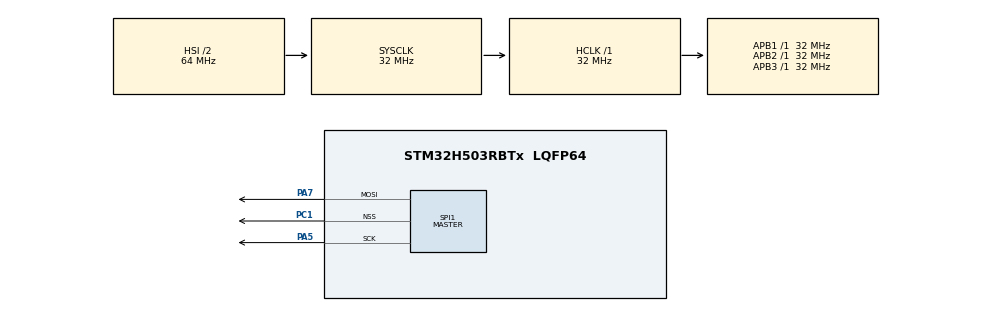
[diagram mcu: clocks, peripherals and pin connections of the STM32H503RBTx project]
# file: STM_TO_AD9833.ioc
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Mcu.Family=STM32H5
Mcu.Name=STM32H503RBTx
Mcu.Package=LQFP64
NVIC.PriorityGroup=NVIC_PRIORITYGROUP_4
PA5.Mode=TX_Only_Simplex_Unidirect_Master
PA5.Signal=SPI1_SCK
PA7.Mode=TX_Only_Simplex_Unidirect_Master
PA7.Signal=SPI1_MOSI
PC1.Mode=NSS_Signal_Hard_Output
PC1.Signal=SPI1_NSS
ProjectManager.HeapSize=0x200
ProjectManager.StackSize=0x400
ProjectManager.TargetToolchain=STM32CubeIDE
RCC.ADCFreq_Value=32000000
RCC.AHBFreq_Value=32000000
RCC.APB1Freq_Value=32000000
RCC.APB1TimFreq_Value=32000000
RCC.APB2Freq_Value=32000000
RCC.APB2TimFreq_Value=32000000
RCC.APB3Freq_Value=32000000
RCC.CSI_VALUE=4000000
RCC.CortexFreq_Value=32000000
RCC.EPOD_VALUE=4000000
RCC.HCLKFreq_Value=32000000
RCC.HSE_VALUE=25000000
RCC.HSI48_VALUE=48000000
RCC.HSI_VALUE=64000000
RCC.LSE_VALUE=32768
RCC.LSIRC_VALUE=32000
RCC.PLL1Q=3
RCC.PLLFRACN=0
RCC.PLLN=32
RCC.SYSCLKFreq_VALUE=32000000
RCC.USBFreq_Value=48000000
RCC.VCOOutputFreq_Value=128000000
SPI1.BaudRatePrescaler=SPI_BAUDRATEPRESCALER_4
SPI1.CLKPolarity=SPI_POLARITY_HIGH
SPI1.CalculateBaudRate=10.666666 MBits/s
SPI1.DataSize=SPI_DATASIZE_8BIT
SPI1.Direction=SPI_DIRECTION_2LINES_TXONLY
SPI1.Mode=SPI_MODE_MASTER
SPI1.VirtualNSS=VM_NSSHARD
SPI1.VirtualType=VM_MASTER
VP_BOOTPATH_VS_BOOTPATH.Mode=BP_Activate
VP_CORTEX_M33_NS_VS_Hclk.Mode=Hclk_Mode
VP_MEMORYMAP_VS_MEMORYMAP.Mode=CurAppReg
VP_PWR_VS_LPOM.Mode=PowerOptimisation
VP_PWR_VS_SECSignals.Mode=Security/Privilege
board=custom

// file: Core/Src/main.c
/* USER CODE BEGIN Header */
/**
  ******************************************************************************
  * @file           : main.c
  * @brief          : Main program body
  ******************************************************************************
  * @attention
  *
  * Copyright (c) 2026 STMicroelectronics.
  * All rights reserved.
  *
  * This software is licensed under terms that can be found in the LICENSE file
  * in the root directory of this software component.
  * If no LICENSE file comes with this software, it is provided AS-IS.
  *
  ******************************************************************************
  */
/* USER CODE END Header */
#include "main.h"

/* USER CODE BEGIN Includes */
#include "AD9833.h"
/* USER CODE END Includes */

SPI_HandleTypeDef hspi1;

void SystemClock_Config(void);
static void MX_GPIO_Init(void);
static void MX_SPI1_Init(void);

int main(void)
{

  /* MCU Configuration--------------------------------------------------------*/

  /* Reset of all peripherals, Initializes the Flash interface and the Systick. */
  HAL_Init();

  /* Configure the system clock */
  SystemClock_Config();

  /* Initialize all configured peripherals */
  MX_GPIO_Init();
  MX_SPI1_Init();
  /* USER CODE BEGIN 2 */
  AD9833_Init(wave_square, 50000, 0);
  /* USER CODE END 2 */

  /* Infinite loop */
  while (1)
  {

  }
}

void SystemClock_Config(void)
{
  RCC_OscInitTypeDef RCC_OscInitStruct = {0};
  RCC_ClkInitTypeDef RCC_ClkInitStruct = {0};

  /** Configure the main internal regulator output voltage
  */
  __HAL_PWR_VOLTAGESCALING_CONFIG(PWR_REGULATOR_VOLTAGE_SCALE3);

  while(!__HAL_PWR_GET_FLAG(PWR_FLAG_VOSRDY)) {}

  /** Initializes the RCC Oscillators according to the specified parameters
  * in the RCC_OscInitTypeDef structure.
  */
  RCC_OscInitStruct.OscillatorType = RCC_OSCILLATORTYPE_HSI|RCC_OSCILLATORTYPE_CSI;
  RCC_OscInitStruct.HSIState = RCC_HSI_ON;
  RCC_OscInitStruct.HSIDiv = RCC_HSI_DIV2;
  RCC_OscInitStruct.HSICalibrationValue = RCC_HSICALIBRATION_DEFAULT;
  RCC_OscInitStruct.CSIState = RCC_CSI_ON;
  RCC_OscInitStruct.CSICalibrationValue = RCC_CSICALIBRATION_DEFAULT;
  RCC_OscInitStruct.PLL.PLLState = RCC_PLL_ON;
  RCC_OscInitStruct.PLL.PLLSource = RCC_PLL1_SOURCE_CSI;
  RCC_OscInitStruct.PLL.PLLM = 1;
  RCC_OscInitStruct.PLL.PLLN = 32;
  RCC_OscInitStruct.PLL.PLLP = 2;
  RCC_OscInitStruct.PLL.PLLQ = 3;
  RCC_OscInitStruct.PLL.PLLR = 2;
  RCC_OscInitStruct.PLL.PLLRGE = RCC_PLL1_VCIRANGE_2;
  RCC_OscInitStruct.PLL.PLLVCOSEL = RCC_PLL1_VCORANGE_WIDE;
  RCC_OscInitStruct.PLL.PLLFRACN = 0;
  if (HAL_RCC_OscConfig(&RCC_OscInitStruct) != HAL_OK)
  {
    Error_Handler();
  }

  /** Initializes the CPU, AHB and APB buses clocks
  */
  RCC_ClkInitStruct.ClockType = RCC_CLOCKTYPE_HCLK|RCC_CLOCKTYPE_SYSCLK
                              |RCC_CLOCKTYPE_PCLK1|RCC_CLOCKTYPE_PCLK2
                              |RCC_CLOCKTYPE_PCLK3;
  RCC_ClkInitStruct.SYSCLKSource = RCC_SYSCLKSOURCE_HSI;
  RCC_ClkInitStruct.AHBCLKDivider = RCC_SYSCLK_DIV1;
  RCC_ClkInitStruct.APB1CLKDivider = RCC_HCLK_DIV1;
  RCC_ClkInitStruct.APB2CLKDivider = RCC_HCLK_DIV1;
  RCC_ClkInitStruct.APB3CLKDivider = RCC_HCLK_DIV1;

  if (HAL_RCC_ClockConfig(&RCC_ClkInitStruct, FLASH_LATENCY_1) != HAL_OK)
  {
    Error_Handler();
  }

  /** Configure the programming delay
  */
  __HAL_FLASH_SET_PROGRAM_DELAY(FLASH_PROGRAMMING_DELAY_0);
}

static void MX_SPI1_Init(void)
{

  /* SPI1 parameter configuration*/
  hspi1.Instance = SPI1;
  hspi1.Init.Mode = SPI_MODE_MASTER;
  hspi1.Init.Direction = SPI_DIRECTION_2LINES_TXONLY;
  hspi1.Init.DataSize = SPI_DATASIZE_8BIT;
  hspi1.Init.CLKPolarity = SPI_POLARITY_HIGH;
  hspi1.Init.CLKPhase = SPI_PHASE_1EDGE;
  hspi1.Init.NSS = SPI_NSS_HARD_OUTPUT;
  hspi1.Init.BaudRatePrescaler = SPI_BAUDRATEPRESCALER_4;
  hspi1.Init.FirstBit = SPI_FIRSTBIT_MSB;
  hspi1.Init.TIMode = SPI_TIMODE_DISABLE;
  hspi1.Init.CRCCalculation = SPI_CRCCALCULATION_DISABLE;
  hspi1.Init.CRCPolynomial = 0x7;
  hspi1.Init.NSSPMode = SPI_NSS_PULSE_ENABLE;
  hspi1.Init.NSSPolarity = SPI_NSS_POLARITY_LOW;
  hspi1.Init.FifoThreshold = SPI_FIFO_THRESHOLD_01DATA;
  hspi1.Init.MasterSSIdleness = SPI_MASTER_SS_IDLENESS_00CYCLE;
  hspi1.Init.MasterInterDataIdleness = SPI_MASTER_INTERDATA_IDLENESS_00CYCLE;
  hspi1.Init.MasterReceiverAutoSusp = SPI_MASTER_RX_AUTOSUSP_DISABLE;
  hspi1.Init.MasterKeepIOState = SPI_MASTER_KEEP_IO_STATE_DISABLE;
  hspi1.Init.IOSwap = SPI_IO_SWAP_DISABLE;
  hspi1.Init.ReadyMasterManagement = SPI_RDY_MASTER_MANAGEMENT_INTERNALLY;
  hspi1.Init.ReadyPolarity = SPI_RDY_POLARITY_HIGH;
  if (HAL_SPI_Init(&hspi1) != HAL_OK)
  {
    Error_Handler();
  }

}

static void MX_GPIO_Init(void)
{

  /* GPIO Ports Clock Enable */
  __HAL_RCC_GPIOC_CLK_ENABLE();
  __HAL_RCC_GPIOA_CLK_ENABLE();

}

void Error_Handler(void)
{
  __disable_irq();
  while (1)
  {
  }
}
